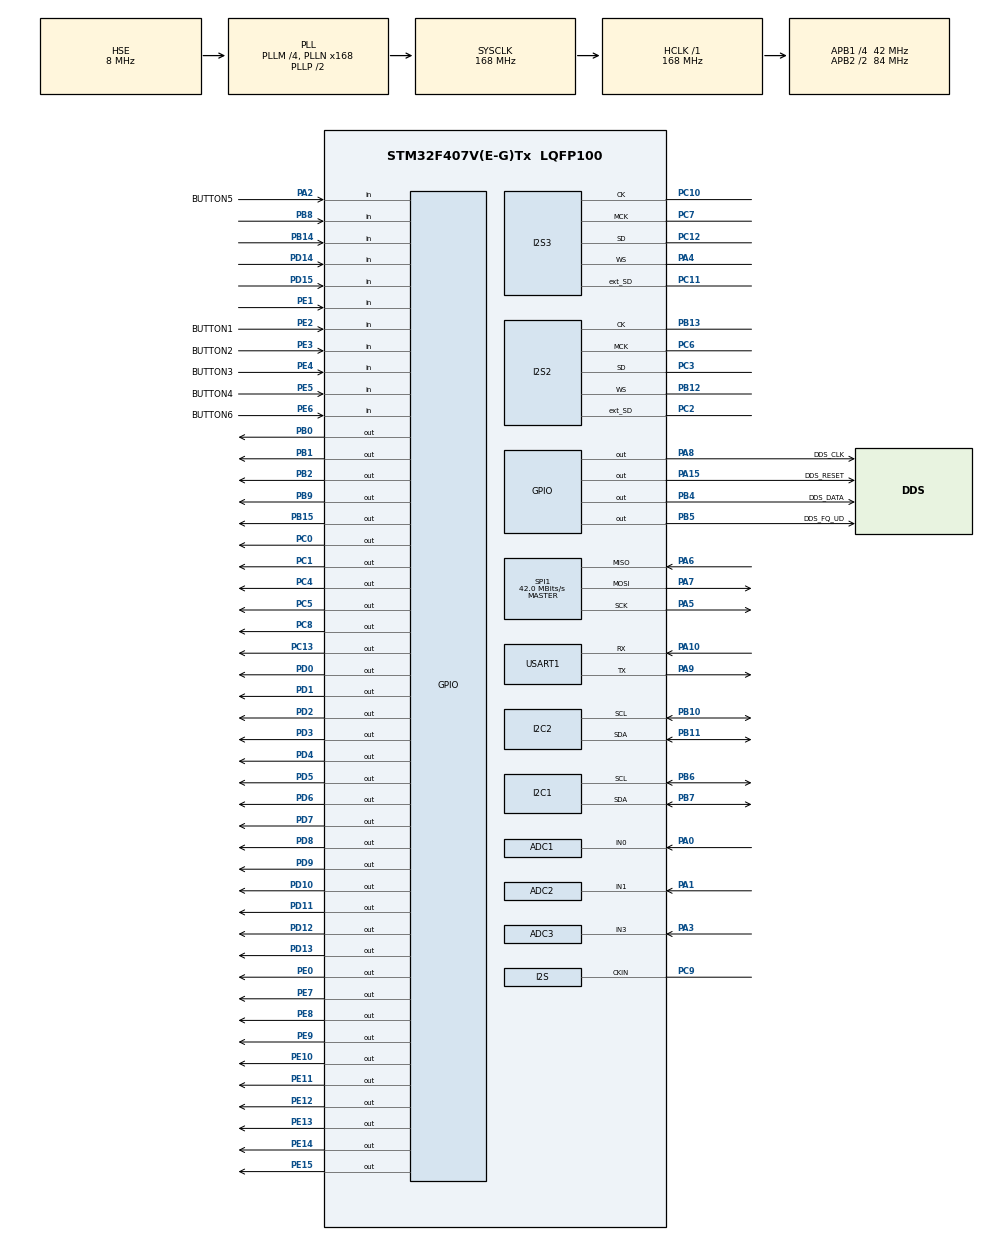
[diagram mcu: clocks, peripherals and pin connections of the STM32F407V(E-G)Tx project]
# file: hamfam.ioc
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ADC1.Channel-4\#ChannelRegularConversion=ADC_CHANNEL_0
ADC1.ClockPrescaler=ADC_CLOCK_SYNC_PCLK_DIV4
ADC1.NbrOfConversionFlag=1
ADC1.Rank-4\#ChannelRegularConversion=1
ADC1.SamplingTime-4\#ChannelRegularConversion=ADC_SAMPLETIME_3CYCLES
ADC1.master=1
ADC2.Channel-0\#ChannelRegularConversion=ADC_CHANNEL_1
ADC2.ClockPrescaler=ADC_CLOCK_SYNC_PCLK_DIV4
ADC2.NbrOfConversionFlag=1
ADC2.Rank-0\#ChannelRegularConversion=1
ADC2.SamplingTime-0\#ChannelRegularConversion=ADC_SAMPLETIME_3CYCLES
ADC3.Channel-0\#ChannelRegularConversion=ADC_CHANNEL_3
ADC3.ClockPrescaler=ADC_CLOCK_SYNC_PCLK_DIV4
ADC3.NbrOfConversionFlag=1
ADC3.Rank-0\#ChannelRegularConversion=1
ADC3.SamplingTime-0\#ChannelRegularConversion=ADC_SAMPLETIME_3CYCLES
FREERTOS.Tasks01=defaultTask,0,128,StartDefaultTask,Default,NULL
FREERTOS.configUSE_PREEMPTION=0
I2S2.ClockSource=I2S_CLOCK_EXTERNAL
I2S2.ErrorAudioFreq=0.0 %
I2S2.FullDuplexMode=I2S_FULLDUPLEXMODE_ENABLE
I2S2.Instance=SPI$Index
I2S2.RealAudioFreq=8.0 KHz
I2S2.VirtualMode=I2S_MODE_MASTER
I2S3.ClockSource=I2S_CLOCK_EXTERNAL
I2S3.ErrorAudioFreq=0.0 %
I2S3.FullDuplexMode=I2S_FULLDUPLEXMODE_ENABLE
I2S3.Instance=SPI$Index
I2S3.RealAudioFreq=8.0 KHz
I2S3.VirtualMode=I2S_MODE_MASTER
Mcu.Family=STM32F4
Mcu.Name=STM32F407V(E-G)Tx
Mcu.Package=LQFP100
NVIC.PriorityGroup=NVIC_PRIORITYGROUP_4
NVIC.TIM3_IRQn=true\:0\:0\:false\:false\:true\:false\:false
NVIC.TimeBase=TIM3_IRQn
NVIC.TimeBaseIP=TIM3
PA0-WKUP.Signal=ADCx_IN0
PA1.Signal=ADCx_IN1
PA10.Mode=Asynchronous
PA10.Signal=USART1_RX
PA13.Mode=Serial_Wire
PA13.Signal=SYS_JTMS-SWDIO
PA14.Mode=Serial_Wire
PA14.Signal=SYS_JTCK-SWCLK
PA15.GPIO_Label=DDS_RESET
PA15.Signal=GPIO_Output
PA2.GPIO_Label=BUTTON5
PA2.GPIO_PuPd=GPIO_PULLUP
PA2.Signal=GPIO_Input
PA3.Signal=ADCx_IN3
PA4.Mode=Full_Duplex_Master
PA4.Signal=I2S3_WS
PA5.Mode=Full_Duplex_Master
PA5.Signal=SPI1_SCK
PA6.Mode=Full_Duplex_Master
PA6.Signal=SPI1_MISO
PA7.Mode=Full_Duplex_Master
PA7.Signal=SPI1_MOSI
PA8.GPIO_Label=DDS_CLK
PA8.GPIO_Speed=GPIO_SPEED_FREQ_VERY_HIGH
PA8.Signal=GPIO_Output
PA9.Mode=Asynchronous
PA9.Signal=USART1_TX
PB0.Signal=GPIO_Output
PB1.Signal=GPIO_Output
PB10.Mode=I2C
PB10.Signal=I2C2_SCL
PB11.Mode=I2C
PB11.Signal=I2C2_SDA
PB12.Mode=Full_Duplex_Master
PB12.Signal=I2S2_WS
PB13.Mode=Full_Duplex_Master
PB13.Signal=I2S2_CK
PB14.Signal=GPIO_Input
PB15.Signal=GPIO_Output
PB2.Signal=GPIO_Output
PB3.Signal=SYS_JTDO-SWO
PB4.GPIO_Label=DDS_DATA
PB4.GPIO_Speed=GPIO_SPEED_FREQ_VERY_HIGH
PB4.PinState=GPIO_PIN_RESET
PB4.Signal=GPIO_Output
PB5.GPIO_Label=DDS_FQ_UD
PB5.GPIO_Speed=GPIO_SPEED_FREQ_VERY_HIGH
PB5.Signal=GPIO_Output
PB6.Mode=I2C
PB6.Signal=I2C1_SCL
PB7.Mode=I2C
PB7.Signal=I2C1_SDA
PB8.Signal=GPIO_Input
PB9.Signal=GPIO_Output
PC0.Signal=GPIO_Output
PC1.Signal=GPIO_Output
PC10.Mode=Full_Duplex_Master
PC10.Signal=I2S3_CK
PC11.Mode=Full_Duplex_Master
PC11.Signal=I2S3_ext_SD
PC12.Mode=Full_Duplex_Master
PC12.Signal=I2S3_SD
PC13-ANTI_TAMP.Signal=GPIO_Output
PC14-OSC32_IN.Mode=LSE-External-Oscillator
PC14-OSC32_IN.Signal=RCC_OSC32_IN
PC15-OSC32_OUT.Mode=LSE-External-Oscillator
PC15-OSC32_OUT.Signal=RCC_OSC32_OUT
PC2.Mode=Full_Duplex_Master
PC2.Signal=I2S2_ext_SD
PC3.Mode=Full_Duplex_Master
PC3.Signal=I2S2_SD
PC4.Signal=GPIO_Output
PC5.Signal=GPIO_Output
PC6.Mode=Master_Clock_Activated
PC6.Signal=I2S2_MCK
PC7.Mode=Master_Clock_Activated
PC7.Signal=I2S3_MCK
PC8.Signal=GPIO_Output
PC9.Mode=Audio_ClockIn
PC9.Signal=I2S_CKIN
PD0.Signal=GPIO_Output
PD1.Signal=GPIO_Output
PD10.Signal=GPIO_Output
PD11.Signal=GPIO_Output
PD12.Signal=GPIO_Output
PD13.Signal=GPIO_Output
PD14.Signal=GPIO_Input
PD15.Signal=GPIO_Input
PD2.Signal=GPIO_Output
PD3.Signal=GPIO_Output
PD4.Signal=GPIO_Output
PD5.Signal=GPIO_Output
PD6.Signal=GPIO_Output
PD7.Signal=GPIO_Output
PD8.Signal=GPIO_Output
PD9.Signal=GPIO_Output
PE0.Signal=GPIO_Output
PE1.Signal=GPIO_Input
PE10.Signal=GPIO_Output
PE11.Signal=GPIO_Output
PE12.Signal=GPIO_Output
PE13.Signal=GPIO_Output
PE14.Signal=GPIO_Output
PE15.Signal=GPIO_Output
PE2.GPIO_Label=BUTTON1
PE2.GPIO_PuPd=GPIO_PULLUP
PE2.Signal=GPIO_Input
PE3.GPIO_Label=BUTTON2
PE3.GPIO_PuPd=GPIO_PULLUP
PE3.Signal=GPIO_Input
PE4.GPIO_Label=BUTTON3
PE4.GPIO_PuPd=GPIO_PULLUP
PE4.Signal=GPIO_Input
PE5.GPIO_Label=BUTTON4
PE5.GPIO_PuPd=GPIO_PULLUP
PE5.Signal=GPIO_Input
PE6.GPIO_Label=BUTTON6
PE6.GPIO_PuPd=GPIO_PULLUP
PE6.Signal=GPIO_Input
PE7.Signal=GPIO_Output
PE8.Signal=GPIO_Output
PE9.Signal=GPIO_Output
PH0-OSC_IN.Mode=HSE-External-Oscillator
PH0-OSC_IN.Signal=RCC_OSC_IN
PH1-OSC_OUT.Mode=HSE-External-Oscillator
PH1-OSC_OUT.Signal=RCC_OSC_OUT
ProjectManager.HeapSize=0x200
ProjectManager.StackSize=0x400
ProjectManager.TargetToolchain=TrueSTUDIO
RCC.48MHZClocksFreq_Value=48000000
RCC.AHBFreq_Value=168000000
RCC.APB1CLKDivider=RCC_HCLK_DIV4
RCC.APB1Freq_Value=42000000
RCC.APB1TimFreq_Value=84000000
RCC.APB2CLKDivider=RCC_HCLK_DIV2
RCC.APB2Freq_Value=84000000
RCC.APB2TimFreq_Value=168000000
RCC.CortexFreq_Value=168000000
RCC.HCLKFreq_Value=168000000
RCC.HSE_VALUE=8000000
RCC.HSI_VALUE=16000000
RCC.I2SClockSource=I2S_CLOCK_EXTERNAL
RCC.PLLM=4
RCC.PLLN=168
RCC.PLLQ=7
RCC.PLLSourceVirtual=RCC_PLLSOURCE_HSE
RCC.RCC_MCO1Source=RCC_MCO1SOURCE_PLLCLK
RCC.SYSCLKFreq_VALUE=168000000
RCC.SYSCLKSource=RCC_SYSCLKSOURCE_PLLCLK
RCC.VCOOutputFreq_Value=336000000
SH.ADCx_IN0.0=ADC1_IN0,IN0
SH.ADCx_IN1.0=ADC2_IN1,IN1
SH.ADCx_IN3.0=ADC3_IN3,IN3
SPI1.BaudRatePrescaler=SPI_BAUDRATEPRESCALER_2
SPI1.CalculateBaudRate=42.0 MBits/s
SPI1.Direction=SPI_DIRECTION_2LINES
SPI1.Mode=SPI_MODE_MASTER
SPI1.VirtualType=VM_MASTER
USART1.VirtualMode=VM_ASYNC
VP_FREERTOS_VS_ENABLE.Mode=Enabled
VP_SYS_VS_tim3.Mode=TIM3
VP_TIM2_VS_ClockSourceITR.Mode=TriggerSource_ITR0
VP_TIM5_VS_ClockSourceITR.Mode=TriggerSource_ITR0
VP_TIM5_VS_ControllerModeClock.Mode=Clock Mode
board=hamfam

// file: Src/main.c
/**
  ******************************************************************************
  * @file           : main.c
  * @brief          : Main program body
  ******************************************************************************
  * This notice applies to any and all portions of this file
  * that are not between comment pairs USER CODE BEGIN and
  * USER CODE END. Other portions of this file, whether
  * inserted by the user or by software development tools
  * are owned by their respective copyright owners.
  *
  * Copyright (c) 2018 STMicroelectronics International N.V.
  * All rights reserved.
  *
  * Redistribution and use in source and binary forms, with or without
  * modification, are permitted, provided that the following conditions are met:
  *
  * 1. Redistribution of source code must retain the above copyright notice,
  *    this list of conditions and the following disclaimer.
  * 2. Redistributions in binary form must reproduce the above copyright notice,
  *    this list of conditions and the following disclaimer in the documentation
  *    and/or other materials provided with the distribution.
  * 3. Neither the name of STMicroelectronics nor the names of other
  *    contributors to this software may be used to endorse or promote products
  *    derived from this software without specific written permission.
  * 4. This software, including modifications and/or derivative works of this
  *    software, must execute solely and exclusively on microcontroller or
  *    microprocessor devices manufactured by or for STMicroelectronics.
  * 5. Redistribution and use of this software other than as permitted under
  *    this license is void and will automatically terminate your rights under
  *    this license.
  *
  * THIS SOFTWARE IS PROVIDED BY STMICROELECTRONICS AND CONTRIBUTORS "AS IS"
  * AND ANY EXPRESS, IMPLIED OR STATUTORY WARRANTIES, INCLUDING, BUT NOT
  * LIMITED TO, THE IMPLIED WARRANTIES OF MERCHANTABILITY, FITNESS FOR A
  * PARTICULAR PURPOSE AND NON-INFRINGEMENT OF THIRD PARTY INTELLECTUAL PROPERTY
  * RIGHTS ARE DISCLAIMED TO THE FULLEST EXTENT PERMITTED BY LAW. IN NO EVENT
  * SHALL STMICROELECTRONICS OR CONTRIBUTORS BE LIABLE FOR ANY DIRECT, INDIRECT,
  * INCIDENTAL, SPECIAL, EXEMPLARY, OR CONSEQUENTIAL DAMAGES (INCLUDING, BUT NOT
  * LIMITED TO, PROCUREMENT OF SUBSTITUTE GOODS OR SERVICES; LOSS OF USE, DATA,
  * OR PROFITS; OR BUSINESS INTERRUPTION) HOWEVER CAUSED AND ON ANY THEORY OF
  * LIABILITY, WHETHER IN CONTRACT, STRICT LIABILITY, OR TORT (INCLUDING
  * NEGLIGENCE OR OTHERWISE) ARISING IN ANY WAY OUT OF THE USE OF THIS SOFTWARE,
  * EVEN IF ADVISED OF THE POSSIBILITY OF SUCH DAMAGE.
  *
  ******************************************************************************
  */
#include "main.h"
#include "stm32f4xx_hal.h"
#include "cmsis_os.h"
#include "adc.h"
#include "i2c.h"
#include "i2s.h"
#include "spi.h"
#include "tim.h"
#include "usart.h"
#include "gpio.h"

/* USER CODE BEGIN Includes */
#include "display.h"
/* USER CODE END Includes */

/* USER CODE BEGIN PV */
/* Private variables ---------------------------------------------------------*/

/* USER CODE END PV */

void SystemClock_Config(void);
void MX_FREERTOS_Init(void);

/* USER CODE BEGIN PFP */
/* Private function prototypes -----------------------------------------------*/

/* USER CODE END PFP */

int main(void)
{

  /* MCU Configuration----------------------------------------------------------*/

  /* Reset of all peripherals, Initializes the Flash interface and the Systick. */
  HAL_Init();

  /* Configure the system clock */
  SystemClock_Config();

  /* Initialize all configured peripherals */
  MX_GPIO_Init();
  MX_ADC1_Init();
  MX_I2C1_Init();
  MX_I2C2_Init();
  MX_ADC2_Init();
  MX_I2S2_Init();
  MX_I2S3_Init();
  MX_SPI1_Init();
  MX_USART1_UART_Init();
  MX_ADC3_Init();
  MX_TIM5_Init();
  MX_TIM2_Init();
  /* USER CODE BEGIN 2 */

  //setVFO(freq);

  /* USER CODE END 2 */

  /* Call init function for freertos objects (in freertos.c) */
  MX_FREERTOS_Init();

  /* Start scheduler */
  osKernelStart();

  /* We should never get here as control is now taken by the scheduler */

  /* Infinite loop */
  while (1)
  {

  }

}

void SystemClock_Config(void)
{

  RCC_OscInitTypeDef RCC_OscInitStruct;
  RCC_ClkInitTypeDef RCC_ClkInitStruct;

    /**Configure the main internal regulator output voltage
    */
  __HAL_RCC_PWR_CLK_ENABLE();

  __HAL_PWR_VOLTAGESCALING_CONFIG(PWR_REGULATOR_VOLTAGE_SCALE1);

    /**Initializes the CPU, AHB and APB busses clocks
    */
  RCC_OscInitStruct.OscillatorType = RCC_OSCILLATORTYPE_HSE;
  RCC_OscInitStruct.HSEState = RCC_HSE_ON;
  RCC_OscInitStruct.PLL.PLLState = RCC_PLL_ON;
  RCC_OscInitStruct.PLL.PLLSource = RCC_PLLSOURCE_HSE;
  RCC_OscInitStruct.PLL.PLLM = 4;
  RCC_OscInitStruct.PLL.PLLN = 168;
  RCC_OscInitStruct.PLL.PLLP = RCC_PLLP_DIV2;
  RCC_OscInitStruct.PLL.PLLQ = 7;
  if (HAL_RCC_OscConfig(&RCC_OscInitStruct) != HAL_OK)
  {
    _Error_Handler(__FILE__, __LINE__);
  }

    /**Initializes the CPU, AHB and APB busses clocks
    */
  RCC_ClkInitStruct.ClockType = RCC_CLOCKTYPE_HCLK|RCC_CLOCKTYPE_SYSCLK
                              |RCC_CLOCKTYPE_PCLK1|RCC_CLOCKTYPE_PCLK2;
  RCC_ClkInitStruct.SYSCLKSource = RCC_SYSCLKSOURCE_PLLCLK;
  RCC_ClkInitStruct.AHBCLKDivider = RCC_SYSCLK_DIV1;
  RCC_ClkInitStruct.APB1CLKDivider = RCC_HCLK_DIV4;
  RCC_ClkInitStruct.APB2CLKDivider = RCC_HCLK_DIV2;

  if (HAL_RCC_ClockConfig(&RCC_ClkInitStruct, FLASH_LATENCY_5) != HAL_OK)
  {
    _Error_Handler(__FILE__, __LINE__);
  }

    /**Configure the Systick interrupt time
    */
  HAL_SYSTICK_Config(HAL_RCC_GetHCLKFreq()/1000);

    /**Configure the Systick
    */
  HAL_SYSTICK_CLKSourceConfig(SYSTICK_CLKSOURCE_HCLK);

  /* SysTick_IRQn interrupt configuration */
  HAL_NVIC_SetPriority(SysTick_IRQn, 15, 0);
}

void HAL_TIM_PeriodElapsedCallback(TIM_HandleTypeDef *htim)
{
  if (htim->Instance == TIM3) {
    HAL_IncTick();
  }
}

void _Error_Handler(char *file, int line)
{
  while(1)
  {
  }
}

/************************ (C) COPYRIGHT STMicroelectronics *****END OF FILE****/

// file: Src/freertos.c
/**
  ******************************************************************************
  * File Name          : freertos.c
  * Description        : Code for freertos applications
  ******************************************************************************
  * This notice applies to any and all portions of this file
  * that are not between comment pairs USER CODE BEGIN and
  * USER CODE END. Other portions of this file, whether
  * inserted by the user or by software development tools
  * are owned by their respective copyright owners.
  *
  * Copyright (c) 2018 STMicroelectronics International N.V.
  * All rights reserved.
  *
  * Redistribution and use in source and binary forms, with or without
  * modification, are permitted, provided that the following conditions are met:
  *
  * 1. Redistribution of source code must retain the above copyright notice,
  *    this list of conditions and the following disclaimer.
  * 2. Redistributions in binary form must reproduce the above copyright notice,
  *    this list of conditions and the following disclaimer in the documentation
  *    and/or other materials provided with the distribution.
  * 3. Neither the name of STMicroelectronics nor the names of other
  *    contributors to this software may be used to endorse or promote products
  *    derived from this software without specific written permission.
  * 4. This software, including modifications and/or derivative works of this
  *    software, must execute solely and exclusively on microcontroller or
  *    microprocessor devices manufactured by or for STMicroelectronics.
  * 5. Redistribution and use of this software other than as permitted under
  *    this license is void and will automatically terminate your rights under
  *    this license.
  *
  * THIS SOFTWARE IS PROVIDED BY STMICROELECTRONICS AND CONTRIBUTORS "AS IS"
  * AND ANY EXPRESS, IMPLIED OR STATUTORY WARRANTIES, INCLUDING, BUT NOT
  * LIMITED TO, THE IMPLIED WARRANTIES OF MERCHANTABILITY, FITNESS FOR A
  * PARTICULAR PURPOSE AND NON-INFRINGEMENT OF THIRD PARTY INTELLECTUAL PROPERTY
  * RIGHTS ARE DISCLAIMED TO THE FULLEST EXTENT PERMITTED BY LAW. IN NO EVENT
  * SHALL STMICROELECTRONICS OR CONTRIBUTORS BE LIABLE FOR ANY DIRECT, INDIRECT,
  * INCIDENTAL, SPECIAL, EXEMPLARY, OR CONSEQUENTIAL DAMAGES (INCLUDING, BUT NOT
  * LIMITED TO, PROCUREMENT OF SUBSTITUTE GOODS OR SERVICES; LOSS OF USE, DATA,
  * OR PROFITS; OR BUSINESS INTERRUPTION) HOWEVER CAUSED AND ON ANY THEORY OF
  * LIABILITY, WHETHER IN CONTRACT, STRICT LIABILITY, OR TORT (INCLUDING
  * NEGLIGENCE OR OTHERWISE) ARISING IN ANY WAY OUT OF THE USE OF THIS SOFTWARE,
  * EVEN IF ADVISED OF THE POSSIBILITY OF SUCH DAMAGE.
  *
  ******************************************************************************
  */

#include "FreeRTOS.h"
#include "task.h"
#include "cmsis_os.h"

/* USER CODE BEGIN Includes */
#include "globals.h"
#include "display.h"
#include "buttons.h"
#include "dds.h"
#include "ham.h"
/* USER CODE END Includes */

osThreadId defaultTaskHandle;

/* USER CODE BEGIN Variables */
osThreadId displayTaskHandle;
osThreadId buttonTaskHandle;

/* USER CODE END Variables */

void StartDefaultTask(void const * argument);

void MX_FREERTOS_Init(void); /* (MISRA C 2004 rule 8.1) */

/* Hook prototypes */

/* Init FreeRTOS */

void MX_FREERTOS_Init(void) {

  /* Create the thread(s) */
  /* definition and creation of defaultTask */
  osThreadDef(defaultTask, StartDefaultTask, osPriorityNormal, 0, 128);
  defaultTaskHandle = osThreadCreate(osThread(defaultTask), NULL);

  /* USER CODE BEGIN RTOS_THREADS */
	osThreadDef(displayTask, StartDisplayTask, osPriorityNormal, 0, 128);
	displayTaskHandle = osThreadCreate(osThread(displayTask), NULL);

	osThreadDef(buttonTask, StartButtonTask, osPriorityNormal, 0, 128);
	buttonTaskHandle = osThreadCreate(osThread(buttonTask), NULL);
  /* USER CODE END RTOS_THREADS */

  /* USER CODE BEGIN RTOS_QUEUES */
	xDisplayQueue = xQueueCreate(10, sizeof(displayMessage_t));
	xButtonQueue = xQueueCreate(30, sizeof(buttonMessage_t));

  /* USER CODE END RTOS_QUEUES */
}

/* StartDefaultTask function */
void StartDefaultTask(void const * argument)
{

  /* USER CODE BEGIN StartDefaultTask */
	uint32_t count = 0;
	uint32_t displayVal = 0;

	displayMessage_t displayMessage;
	buttonMessage_t buttonMessage;

	BaseType_t xStatus;

	uint8_t fUpHold = 0;
	uint8_t fDownHold = 0;

	uint8_t bandNum = 4;
	uint8_t classType = CLASS_EXTRA;

	uint32_t freq = get_default_freq(bandNum);
	uint32_t oldFreq = freq;
	setVFO(freq);

	displayVal = freq / 100;
	displayMessage.displayDestination = DIGIT_DISPLAY;
	displayMessage.val = displayVal;
	xStatus = xQueueSendToBack(xDisplayQueue, &displayMessage, 0);

	if (xStatus != pdPASS) {
		//todo: add an assert or wait
	}

	for (;;) {
		count++;

		if (fUpHold == 1)
			freq += 1000;

		if (fDownHold == 1)
			freq -= 1000;

		if (uxQueueMessagesWaiting(xButtonQueue) > 0) {
			xStatus = xQueueReceive(xButtonQueue, &buttonMessage, 0);
			if (xStatus == pdPASS) {

				//BAND UP BUTTON
				if (buttonMessage.buttonName == BUTTON1) {
					if (buttonMessage.buttonEvent == BUTTON_PRESS) {
						bandNum = next_band(bandNum, classType);
						freq = get_default_freq(bandNum);
					}
				}

				//BAND DOWN BUTTON
				if (buttonMessage.buttonName == BUTTON2) {
					if (buttonMessage.buttonEvent == BUTTON_PRESS) {
						bandNum = previous_band(bandNum, classType);
						freq = get_default_freq(bandNum);
					}
				}

				//FREQ UP BUTTON
				if (buttonMessage.buttonName == BUTTON4) {

					if (buttonMessage.buttonEvent == BUTTON_PRESS)
						freq += 100;
					if (buttonMessage.buttonEvent == BUTTON_HOLD)
						fUpHold = 1;
					if (buttonMessage.buttonEvent == BUTTON_RELEASE)
						fUpHold = 0;
				}

				//FREQ UP BUTTON
				if (buttonMessage.buttonName == BUTTON6) {

					if (buttonMessage.buttonEvent == BUTTON_PRESS)
						freq -= 100;
					if (buttonMessage.buttonEvent == BUTTON_HOLD)
						fDownHold = 1;
					if (buttonMessage.buttonEvent == BUTTON_RELEASE)
						fDownHold = 0;

				}

				//FREQ SWEEP BUTTON
				if (buttonMessage.buttonName == BUTTON5) {

					//start a sweep sequence
					if (buttonMessage.buttonEvent == BUTTON_HOLD) {
						uint32_t swp_start_freq = 1000000;
						uint32_t swp_stop_freq  = 30000000;
						uint32_t swp_steps = 100;
						uint32_t swp_duration = 500; //ms
						uint32_t swp_current_freq = swp_start_freq;

						HAL_GPIO_WritePin(GPIOC, GPIO_PIN_0, GPIO_PIN_SET); //used to trigger the scope
						for(uint32_t step = 0; step < swp_steps; step++) {
							swp_current_freq = swp_start_freq + (swp_stop_freq-swp_start_freq)/swp_steps*step;
							setVFO(swp_current_freq);
						}
						HAL_GPIO_WritePin(GPIOC, GPIO_PIN_0, GPIO_PIN_RESET);

					}

				}
			}

		}

		if (freq != oldFreq) {

			freq = check_freq_range(freq, bandNum, classType); //make sure the freq is a valid HAM frequency

			oldFreq = freq;
			setVFO(freq);
			displayVal = freq / 100;
			displayMessage.displayDestination = DIGIT_DISPLAY;
			displayMessage.val = displayVal;

			xStatus = xQueueSendToBack(xDisplayQueue, &displayMessage, 0);
			if (xStatus != pdPASS) {
				//todo: add an assert or wait
			}

		}

		osDelay(50);
	}
}

  /* USER CODE END StartDefaultTask */

/************************ (C) COPYRIGHT STMicroelectronics *****END OF FILE****/
